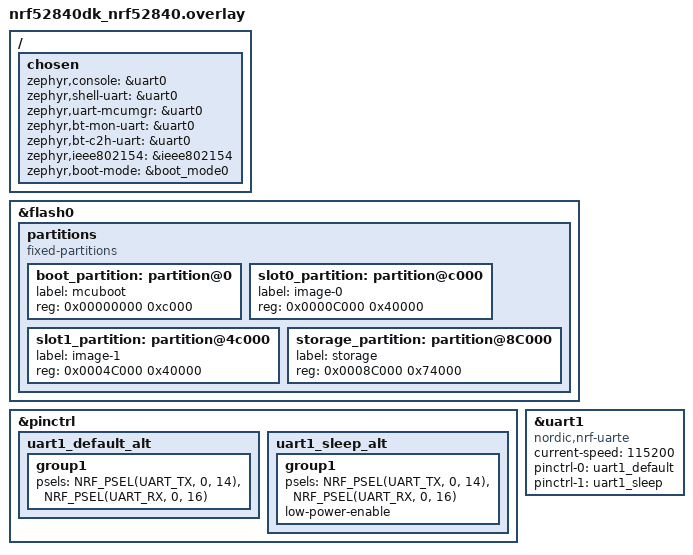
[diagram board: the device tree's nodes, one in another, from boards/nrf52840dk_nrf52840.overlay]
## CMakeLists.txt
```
cmake_minimum_required(VERSION 3.20.0)

set(CMAKE_EXPORT_COMPILE_COMMANDS ON)
find_package(Zephyr REQUIRED HINTS $ENV{ZEPHYR_BASE})
project(sample_with_mcuboot)

test_sysbuild()

target_sources(app PRIVATE src/main.c)
```

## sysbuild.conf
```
# Sysbuild configuration file.

# Enable MCUboot using overwrite only mode for this sample.
SB_CONFIG_BOOTLOADER_MCUBOOT=y
SB_CONFIG_MCUBOOT_MODE_OVERWRITE_ONLY=y
SB_CONFIG_MCUBOOT_MODE_SINGLE_APP=n

SB_CONFIG_BOOT_SIGNATURE_TYPE_ECDSA_P256=n
SB_CONFIG_BOOT_SIGNATURE_TYPE_NONE=y
SB_CONFIG_BOOT_SIGNATURE_TYPE_RSA=n

#
# Sysbuild image configuration
#

#
# Modules
#

SB_CONFIG_WARN_EXPERIMENTAL=y
SB_CONFIG_WARN_DEPRECATED=y

SB_CONFIG_BOOTLOADER_NONE=n 
SB_CONFIG_MCUBOOT_MODE_SINGLE_APP=n
# SB_CONFIG_MCUBOOT_MODE_SWAP_USING_OFFSET is not set
# SB_CONFIG_MCUBOOT_MODE_SWAP_USING_MOVE is not set
# SB_CONFIG_MCUBOOT_MODE_SWAP_WITHOUT_SCRATCH is not set
# SB_CONFIG_MCUBOOT_MODE_SWAP_SCRATCH is not set
SB_CONFIG_MCUBOOT_MODE_OVERWRITE_ONLY=y
# SB_CONFIG_MCUBOOT_MODE_DIRECT_XIP is not set
# SB_CONFIG_MCUBOOT_MODE_DIRECT_XIP_WITH_REVERT is not set
# SB_CONFIG_MCUBOOT_MODE_RAM_LOAD is not set
# SB_CONFIG_MCUBOOT_MODE_FIRMWARE_UPDATER=y
# SB_CONFIG_MCUBOOT_MODE_SINGLE_APP_RAM_LOAD is not set
SB_CONFIG_BOOT_SIGNATURE_TYPE_NONE=y
# SB_CONFIG_BOOT_SIGNATURE_TYPE_RSA is not set
# SB_CONFIG_BOOT_SIGNATURE_TYPE_ECDSA_P256 is not set
# SB_CONFIG_BOOT_SIGNATURE_TYPE_ED25519 is not set
```

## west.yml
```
manifest:
  version: 0.8

  projects:
    - name: zephyr
      url: https://github.com/zephyrproject-rtos/zephyr 
      revision: main
      import:
        file: west.yml 
        path-prefix: deps 
        name-allowlist:
          - zephyr
          - cmsis
          - cmsis_6 
          - hal_nordic
          - mcuboot
          - zcbor
          - mbedtls 

  self:
    path: app
```

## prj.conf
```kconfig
CONFIG_CBPRINTF_NANO=n

## subsys/logging/Kconfig
CONFIG_LOG=y
CONFIG_LOG_MODE_MINIMAL=n

## Kconfig.zephyr
CONFIG_STD_C23=y
CONFIG_CODING_GUIDELINE_CHECK=y
# CONFIG_DEBUG_OPTIMIZATIONS=y
CONFIG_SIZE_OPTIMIZATIONS_AGGRESSIVE=y
CONFIG_COMPILER_WARNINGS_AS_ERRORS=n  #  Kernal build fails
CONFIG_DEPRECATION_TEST=y
CONFIG_COMPILER_SAVE_TEMPS=y
CONFIG_MISRA_SANE=y
CONFIG_ASSERT_ON_ERRORS=y
# CONFIG_RUNTIME_ERROR_CHECK=y
CONFIG_OUTPUT_PRINT_MEMORY_USAGE=y
CONFIG_BUILD_OUTPUT_META=y
CONFIG_IS_BOOTLOADER=n
CONFIG_LEGACY_GENERATED_INCLUDE_PATH=n

# MCUBoot Kconfig.mcuboot 
CONFIG_BOOTLOADER_MCUBOOT=y
#CONFIG_MCUBOOT_IMGTOOL_OVERWRITE_ONLY=y
CONFIG_MCUBOOT_GENERATE_UNSIGNED_IMAGE=y
# CONFIG_MCUBOOT_GENERATE_CONFIRMED_IMAGE=y
#CONFIG_MCUBOOT_BOOTLOADER_MODE_SINGLE_APP=n
#CONFIG_MCUBOOT_BOOTLOADER_MODE_FIRMWARE_UPDATER=y
CONFIG_BOOT_IMAGE_ACCESS_HOOKS=n

#
#CONFIG_ACPI_SHELL=y 

# Shell Kconfig
CONFIG_SHELL=y
CONFIG_SHELL_MINIMAL=n  #  enable comfort features

# Flash
CONFIG_FLASH=y
CONFIG_STREAM_FLASH=y
CONFIG_STREAM_FLASH_PROGRESS=y
CONFIG_FLASH_MAP=y
CONFIG_STREAM_FLASH_INSPECT=y

# DFU Kconfig
CONFIG_IMG_MANAGER=y
CONFIG_MCUBOOT_IMG_MANAGER=y
CONFIG_MCUBOOT_SHELL=y
CONFIG_IMG_BLOCK_BUF_SIZE=1024
CONFIG_IMG_ERASE_PROGRESSIVELY=y
CONFIG_IMG_ENABLE_IMAGE_CHECK=y
CONFIG_UPDATEABLE_IMAGE_NUMBER=1


CONFIG_COUNTER=y
#CONFIG_EDAC=y 
CONFIG_HWINFO=y
CONFIG_I2C=y
#CONFIG_PLIC=y
CONFIG_LED=y
CONFIG_PWM=y
CONFIG_REGULATOR=y
CONFIG_RTC=y
CONFIG_SENSOR=y
CONFIG_STEPPER=y
CONFIG_CRC=y
#CONFIG_TASK_WDT=y
CONFIG_STREAM_FLASH=y
CONFIG_STDOUT_CONSOLE=y
CONFIG_FLASH=y
CONFIG_FLASH_MAP=y
CONFIG_SETTINGS=y
CONFIG_GPIO=y
CONFIG_RESET=y
# CONFIG_ASSERT is not set
# CONFIG_DEVICE_DEPS is not set
CONFIG_CONSOLE=y
CONFIG_REBOOT=y

CONFIG_SETTINGS_RUNTIME=y
CONFIG_NVS=y
CONFIG_SETTINGS_NVS=y
CONFIG_HEAP_MEM_POOL_SIZE=256
CONFIG_MPU_ALLOW_FLASH_WRITE=y


CONFIG_SETTINGS_SHELL=y
CONFIG_KERNEL_SHELL=y
CONFIG_CRC_SHELL=y
#CONFIG_TASK_WDT_SHELL=y
CONFIG_ISR_TABLE_SHELL=y
CONFIG_POSIX_ENV_SHELL=y
CONFIG_POSIX_UNAME_SHELL=y
CONFIG_SENSOR_SHELL=y
CONFIG_RTC_SHELL=y
#CONFIG_PLIC_SHELL=y
CONFIG_STEPPER_SHELL=y
CONFIG_ADC_SHELL=y
CONFIG_DAC_SHELL=y 
CONFIG_UART_SHELL=y 
CONFIG_PWM_SHELL=y 
#CONFIG_EDAC_SHELL=y
CONFIG_LED_SHELL=y
CONFIG_REGULATOR_SHELL=y
CONFIG_I2C_SHELL=y
CONFIG_HWINFO_SHELL=y
CONFIG_FLASH_SHELL=y
CONFIG_FLASH_SHELL_TEST_COMMANDS=y
CONFIG_COUNTER_SHELL=y
CONFIG_DEVICE_SHELL=y
CONFIG_DATE_SHELL=y
CONFIG_DEVMEM_SHELL=y
CONFIG_APP_VERSION_SHELL=y
CONFIG_KERNEL_SHELL=y


CONFIG_GEN_ISR_TABLES=y
CONFIG_INIT_STACKS=y
CONFIG_TIMESLICE_SIZE=20
CONFIG_FLASH_LOAD_OFFSET=0xc000
CONFIG_SYS_CLOCK_EXISTS=y
CONFIG_INIT_ARCH_HW_AT_BOOT=y
# CONFIG_BUILD_OUTPUT_S19 is not set
CONFIG_BUILD_OUTPUT_HEX=y
# CONFIG_POWER_DOMAIN is not set
# CONFIG_MFD is not set
# CONFIG_SCHED_CPU_MASK is not set
#
# Modules
#
# CONFIG_BUILD_ONLY_NO_BLOBS is not set

#CONFIG_MCUBOOT_IMGTOOL_OVERWRITE_ONLY=y

#
# On board MCUboot operation mode
#
# CONFIG_MCUBOOT_BOOTLOADER_MODE_SINGLE_APP is not set
# CONFIG_MCUBOOT_BOOTLOADER_MODE_SWAP_USING_OFFSET is not set
# CONFIG_MCUBOOT_BOOTLOADER_MODE_SWAP_USING_MOVE is not set
# CONFIG_MCUBOOT_BOOTLOADER_MODE_SWAP_WITHOUT_SCRATCH is not set
# CONFIG_MCUBOOT_BOOTLOADER_MODE_SWAP_SCRATCH is not set
CONFIG_MCUBOOT_BOOTLOADER_MODE_OVERWRITE_ONLY=y
# CONFIG_MCUBOOT_BOOTLOADER_MODE_RAM_LOAD is not set
# CONFIG_MCUBOOT_BOOTLOADER_MODE_RAM_LOAD_WITH_REVERT is not set
# CONFIG_MCUBOOT_BOOTLOADER_MODE_DIRECT_XIP is not set
# CONFIG_MCUBOOT_BOOTLOADER_MODE_DIRECT_XIP_WITH_REVERT is not set
# CONFIG_MCUBOOT_BOOTLOADER_MODE_FIRMWARE_UPDATER is not set
# CONFIG_MCUBOOT_BOOTLOADER_MODE_SINGLE_APP_RAM_LOAD is not set
# CONFIG_MCUBOOT_BOOTLOADER_NO_DOWNGRADE is not set
# CONFIG_MCUBOOT_BOOTLOADER_USES_SHA512 is not set
# CONFIG_MCUBOOT_BOOTLOADER_SIGNATURE_TYPE_PURE is not set
# end of On board MCUboot operation mode

CONFIG_MCUBOOT_BOOTUTIL_LIB=y
#
# DSP Options
#
# end of DSP Options

#
# Floating Point Options
#
# end of Floating Point Options

#
# Cache Options
#
# end of Cache Options

#
# Kernel Debugging and Metrics
#
CONFIG_BOOT_BANNER=y
CONFIG_BOOT_BANNER_STRING="Booting Zephyr OS build"
CONFIG_BOOT_DELAY=0

#
# Device Options
#
# CONFIG_DEVICE_MUTABLE is not set
CONFIG_DEVICE_DT_METADATA=y
CONFIG_DEVICE_DEINIT_SUPPORT=y
# end of Device Options

#
# Device Drivers
#
CONFIG_ADC=y
# CONFIG_AUDIO is not set
# CONFIG_AUXDISPLAY is not set
# CONFIG_BBRAM is not set
# CONFIG_CAN is not set
# CONFIG_CHARGER is not set
CONFIG_UART_CONSOLE=y
# CONFIG_UART_CONSOLE_DEBUG_SERVER_HOOKS is not set
# CONFIG_UART_CONSOLE_MCUMGR is not set
# CONFIG_RAM_CONSOLE is not set
# CONFIG_IPM_CONSOLE_SENDER is not set
# CONFIG_IPM_CONSOLE_RECEIVER is not set
# CONFIG_UART_MCUMGR is not set
# CONFIG_EFI_CONSOLE is not set
# CONFIG_COREDUMP_DEVICE is not set
#CONFIG_CRC_DRIVER=n
# CONFIG_CRYPTO is not set
CONFIG_DAC=y
# CONFIG_DAI is not set
# CONFIG_DEBUG_DRIVER is not set
# CONFIG_DISK_DRIVERS is not set
# CONFIG_DISPLAY is not set
# CONFIG_DMA is not set
# CONFIG_DP_DRIVER is not set
# CONFIG_EDAC is not set
# CONFIG_EEPROM is not set
# CONFIG_ENTROPY_GENERATOR is not set
# CONFIG_ESPI is not set

#
# Firmware drivers
#
# CONFIG_ARM_SCMI is not set
# end of Firmware drivers

# CONFIG_FPGA is not set
# CONFIG_FUEL_GAUGE is not set
# CONFIG_GNSS is not set
CONFIG_GPIO_SHELL=y
CONFIG_GPIO_SHELL_INFO_CMD=y
CONFIG_GPIO_SHELL_TOGGLE_CMD=y
CONFIG_GPIO_SHELL_BLINK_CMD=y
# CONFIG_GPIO_GET_DIRECTION is not set
# CONFIG_GPIO_GET_CONFIG is not set
# CONFIG_GPIO_HOGS is not set
# CONFIG_GPIO_ENABLE_DISABLE_INTERRUPT is not set

#
# Timer drivers
#
# CONFIG_TIMER_READS_ITS_FREQUENCY_AT_RUNTIME is not set
# CONFIG_SYSTEM_CLOCK_SLOPPY_IDLE is not set

# CONFIG_USB_BC12 is not set
# CONFIG_UDC_DRIVER is not set
# CONFIG_UHC_DRIVER is not set
# CONFIG_UVB is not set
# CONFIG_USB_DEVICE_DRIVER is not set

#
# USB common
#
# end of USB common

# CONFIG_USBC_TCPC_DRIVER is not set
# CONFIG_USBC_VBUS_DRIVER is not set
# CONFIG_USBC_PPC_DRIVER is not set
# CONFIG_VIDEO is not set
# CONFIG_VIRTIO is not set
# CONFIG_VIRTUALIZATION is not set
# CONFIG_W1 is not set
# CONFIG_TEE is not set
# end of Device Drivers


#
# C++ Language Support
#
# CONFIG_CPP is not set
# end of C++ Language Support

#
# Additional libraries
#

#
# Hash Function Support
#
# CONFIG_SYS_HASH_FUNC32 is not set
# end of Hash Function Support

#
# Hashmap (Hash Table) Support
#
# CONFIG_SYS_HASH_MAP is not set
# end of Hashmap (Hash Table) Support

#
# Heap and Memory Allocation
#
# CONFIG_SYS_HEAP_STRESS is not set
# CONFIG_SYS_HEAP_INFO is not set
CONFIG_SYS_HEAP_ALLOC_LOOPS=3
# CONFIG_SYS_HEAP_RUNTIME_STATS is not set
CONFIG_SYS_HEAP_ARRAY_SIZE=0
# CONFIG_SYS_HEAP_LISTENER is not set
CONFIG_SYS_HEAP_SMALL_ONLY=y
# CONFIG_SYS_HEAP_BIG_ONLY is not set
# CONFIG_SYS_HEAP_AUTO is not set
# CONFIG_MULTI_HEAP is not set
# CONFIG_SHARED_MULTI_HEAP is not set
# end of Heap and Memory Allocation

#
# Memory Blocks
#
CONFIG_SYS_MEM_BLOCKS=y
# end of Memory Blocks

# CONFIG_NET_BUF is not set

#
# OS Support Library
#
# CONFIG_FDTABLE is not set
CONFIG_CBPRINTF_COMPLETE=y
# CONFIG_CBPRINTF_NANO is not set
CONFIG_CBPRINTF_FULL_INTEGRAL=y
# CONFIG_CBPRINTF_REDUCED_INTEGRAL is not set
CONFIG_CBPRINTF_FP_SUPPORT=y
# CONFIG_CBPRINTF_FP_A_SUPPORT is not set
# CONFIG_CBPRINTF_LIBC_SUBSTS is not set
# CONFIG_CBPRINTF_PACKAGE_LONGDOUBLE is not set
# CONFIG_ZVFS is not set
# end of OS Support Library

#
# POSIX API Support
#


#
# POSIX Shell Utilities
#
CONFIG_POSIX_ENV_SHELL=y
# end of POSIX Shell Utilities
# end of POSIX API Support

# CONFIG_OPENAMP_RSC_TABLE is not set
# CONFIG_SMF is not set
CONFIG_LIBGCC_RTLIB=y

#
# Utility Library
#
# CONFIG_JSON_LIBRARY is not set
CONFIG_RING_BUFFER=y
# CONFIG_RING_BUFFER_LARGE is not set
CONFIG_NOTIFY=y
# CONFIG_BASE64 is not set
CONFIG_ONOFF=y
# CONFIG_UTF8 is not set
# CONFIG_COBS is not set
# end of Utility Library

#
# Universally Unique Identifier (UUID)
#
# CONFIG_UUID is not set
# end of Universally Unique Identifier (UUID)

# CONFIG_MIN_HEAP is not set
# end of Additional libraries

#
# Subsystems and OS Services
#
# CONFIG_BINDESC is not set
# CONFIG_BT is not set

#
# Controller Area Network (CAN) bus subsystem
#
# end of Controller Area Network (CAN) bus subsystem

# CONFIG_CONSOLE_SUBSYS is not set
# CONFIG_CPU_LOAD_METRIC is not set
# CONFIG_CRC is not set
# CONFIG_DAP is not set

#
# System Monitoring Options
#
# CONFIG_THREAD_ANALYZER is not set
# end of System Monitoring Options

#
# Debugging Options
#
# CONFIG_DEBUG is not set
# CONFIG_UBSAN is not set
# CONFIG_STACK_USAGE is not set
CONFIG_PRINTK=y
CONFIG_EARLY_CONSOLE=y
# CONFIG_FORCE_NO_ASSERT is not set
CONFIG_ASSERT_VERBOSE=y
# CONFIG_ASSERT_NO_FILE_INFO is not set
# CONFIG_ASSERT_NO_COND_INFO is not set
# CONFIG_ASSERT_NO_MSG_INFO is not set
# CONFIG_ASSERT_TEST is not set
# CONFIG_OVERRIDE_FRAME_POINTER_DEFAULT is not set
# CONFIG_DEBUG_THREAD_INFO is not set
# CONFIG_DEBUG_COREDUMP is not set
# CONFIG_SYMTAB is not set
# end of Debugging Options

# CONFIG_MIPI_STP_DECODER is not set
# CONFIG_CS_TRACE_DEFMT is not set
# CONFIG_CPU_LOAD is not set
CONFIG_CPU_LOAD_LOG_PERIODICALLY=0
# CONFIG_DISK_ACCESS is not set
# CONFIG_DSP is not set
# CONFIG_EMUL is not set
# CONFIG_CHARACTER_FRAMEBUFFER is not set

#
# File Systems
#
# CONFIG_FILE_SYSTEM_LIB_LINK is not set
# CONFIG_FILE_SYSTEM is not set
# end of File Systems

# CONFIG_GNSS_RTK is not set

#
# Inter Processor Communication
#
# CONFIG_RPMSG_SERVICE is not set
# CONFIG_IPC_SERVICE is not set
# end of Inter Processor Communication

# CONFIG_JWT is not set
# CONFIG_LLEXT is not set
# CONFIG_LLEXT_EDK is not set

#
# Logging
#
CONFIG_LOG_CORE_INIT_PRIORITY=0
CONFIG_LOG_MODE_DEFERRED=y
# CONFIG_LOG_MODE_IMMEDIATE is not set
# CONFIG_LOG_MODE_MINIMAL is not set
# CONFIG_LOG_FRONTEND is not set
# CONFIG_LOG_FRONTEND_OPT_API is not set
# CONFIG_LOG_CUSTOM_HEADER is not set
# CONFIG_LOG_MULTIDOMAIN is not set
CONFIG_LOG_FLUSH_SLEEP_US=10000

#
# Logging levels filtering
#
CONFIG_LOG_RUNTIME_FILTERING=y
CONFIG_LOG_DEFAULT_LEVEL=3
CONFIG_LOG_OVERRIDE_LEVEL=0
CONFIG_LOG_MAX_LEVEL=4
# end of Logging levels filtering

#
# Processing
#
CONFIG_LOG_PRINTK=y
CONFIG_LOG_MODE_OVERFLOW=y
# CONFIG_LOG_BLOCK_IN_THREAD is not set
CONFIG_LOG_PROCESS_TRIGGER_THRESHOLD=10
CONFIG_LOG_PROCESS_THREAD=y
CONFIG_LOG_PROCESS_THREAD_STARTUP_DELAY_MS=0
CONFIG_LOG_PROCESS_THREAD_SLEEP_MS=1000
CONFIG_LOG_PROCESS_THREAD_STACK_SIZE=768
# CONFIG_LOG_PROCESS_THREAD_CUSTOM_PRIORITY is not set
CONFIG_LOG_BUFFER_SIZE=1024
CONFIG_LOG_TRACE_SHORT_TIMESTAMP=y
# CONFIG_LOG_TIMESTAMP_64BIT is not set
# CONFIG_LOG_TIMESTAMP_USE_REALTIME is not set
# CONFIG_LOG_SPEED is not set
# end of Processing

#
# Output Formatting
#

#
# Prepend non-hexdump log message with function name
#
# CONFIG_LOG_FUNC_NAME_PREFIX_ERR is not set
# CONFIG_LOG_FUNC_NAME_PREFIX_WRN is not set
# CONFIG_LOG_FUNC_NAME_PREFIX_INF is not set
CONFIG_LOG_FUNC_NAME_PREFIX_DBG=y
# end of Prepend non-hexdump log message with function name

# CONFIG_LOG_MIPI_SYST_ENABLE is not set
# CONFIG_LOG_THREAD_ID_PREFIX is not set
# CONFIG_LOG_CUSTOM_FORMAT_SUPPORT is not set
CONFIG_LOG_BACKEND_SHOW_COLOR=y
# CONFIG_LOG_INFO_COLOR_GREEN is not set
# CONFIG_LOG_DBG_COLOR_BLUE is not set
CONFIG_LOG_TAG_MAX_LEN=0
CONFIG_LOG_OUTPUT_FORMAT_TIME_TIMESTAMP=y
# CONFIG_LOG_OUTPUT_FORMAT_LINUX_TIMESTAMP is not set
# CONFIG_LOG_OUTPUT_FORMAT_CUSTOM_TIMESTAMP is not set
# end of Output Formatting

#
# Backends
#
# CONFIG_LOG_BACKEND_SWO is not set
# CONFIG_LOG_BACKEND_UART is not set
# CONFIG_LOG_BACKEND_IPC_SERVICE is not set
# end of Backends

#
# Misc
#
# CONFIG_LOG_CMDS is not set
# CONFIG_LOG_USE_VLA is not set
CONFIG_LOG_SIMPLE_MSG_OPTIMIZE=y
# CONFIG_LOG_ALWAYS_RUNTIME is not set
# CONFIG_LOG_FMT_SECTION is not set
# CONFIG_LOG_FMT_STRING_VALIDATE is not set
# CONFIG_LOG_MEM_UTILIZATION is not set
CONFIG_LOG_FAILURE_REPORT_PERIOD=1000
# end of Misc

CONFIG_LOG_RATELIMIT=y
CONFIG_LOG_RATELIMIT_INTERVAL_MS=5000
CONFIG_LOG_OUTPUT=y
# end of Logging

CONFIG_MEM_ATTR=y
# CONFIG_MEM_ATTR_HEAP is not set

#
# Device Management
#

#
# Host command handler subsystem
#
# CONFIG_EC_HOST_CMD is not set
# end of Host command handler subsystem

# CONFIG_OSDP is not set
# end of Device Management

# CONFIG_MODBUS is not set
# CONFIG_MODEM_MODULES is not set

#
# Networking
#
# CONFIG_NETWORKING is not set
# end of Networking

#
# Power Management
#
# CONFIG_PM_POLICY_LATENCY_STANDALONE is not set
# end of Power Management

#
# Platform Management Communications Infrastructure (PMCI)
#
# CONFIG_MCTP is not set
# end of Platform Management Communications Infrastructure (PMCI)

#
# Portability
#
# end of Portability

# CONFIG_PROFILING is not set


CONFIG_RTIO=y

#
# SD
#
# CONFIG_MMC_STACK is not set
# CONFIG_SDMMC_STACK is not set
# CONFIG_SDIO_STACK is not set
# end of SD

# CONFIG_SECURE_STORAGE is not set
# CONFIG_SETTINGS
CONFIG_SHELL_MINIMAL=n
CONFIG_SHELL_DEVICE_HELPERS=y
# CONFIG_SHELL_THREAD_PRIORITY_OVERRIDE is not set
CONFIG_KERNEL_SHELL_PANIC_CMD=y
# CONFIG_STATS is not set

#
# Storage
#
CONFIG_FLASH_MAP=y
CONFIG_STREAM_FLASH=y
# end of Storage

# CONFIG_TASK_WDT is not set

#
# Testing
#
# CONFIG_ZTEST is not set
# CONFIG_ZTEST_MOCKING is not set
# CONFIG_ZTRESS is not set
# CONFIG_TEST is not set
# CONFIG_FORCE_COVERAGE is not set
# CONFIG_TEST_USERSPACE is not set
# end of Testing

# CONFIG_TIMING_FUNCTIONS is not set
# CONFIG_TRACING is not set
# CONFIG_USB_DEVICE_STACK is not set
# CONFIG_USB_DEVICE_STACK_NEXT is not set
# CONFIG_USB_HOST_STACK is not set
# CONFIG_USBC_STACK is not set
# CONFIG_ZBUS is not set
# CONFIG_MODULES is not set
# end of Subsystems and OS Services


#
# Build and Link Features
#


#
# Compiler Options
#
# CONFIG_STD_C90 is not set
# CONFIG_STD_C99 is not set
# CONFIG_STD_C11 is not set
# CONFIG_STD_C17 is not set
# CONFIG_GNU_C_EXTENSIONS is not set
# CONFIG_COMPILER_FREESTANDING is not set
# CONFIG_SIZE_OPTIMIZATIONS is not set
# CONFIG_SPEED_OPTIMIZATIONS is not set
# CONFIG_DEBUG_OPTIMIZATIONS is not set
# CONFIG_NO_OPTIMIZATIONS is not set
# CONFIG_COMPILER_WARNINGS_AS_ERRORS is not set
CONFIG_COMPILER_TRACK_MACRO_EXPANSION=y
CONFIG_COMPILER_COLOR_DIAGNOSTICS=y
# CONFIG_FORTIFY_SOURCE_NONE is not set
CONFIG_FORTIFY_SOURCE_COMPILE_TIME=y
# CONFIG_FORTIFY_SOURCE_RUN_TIME is not set
# end of Compiler Options

# CONFIG_NO_RUNTIME_CHECKS is not set
# CONFIG_RUNTIME_ERROR_CHECKS is not set

#
# Build Options
#
CONFIG_OUTPUT_STAT=y
# CONFIG_OUTPUT_SYMBOLS is not set
# CONFIG_CLEANUP_INTERMEDIATE_FILES is not set
CONFIG_BUILD_GAP_FILL_PATTERN=0xDE
# CONFIG_BUILD_NO_GAP_FILL is not set
# CONFIG_BUILD_OUTPUT_HEX_GAP_FILL is not set
# CONFIG_BUILD_OUTPUT_EXE is not set
# CONFIG_BUILD_OUTPUT_S19_GAP_FILL is not set
# CONFIG_BUILD_OUTPUT_UF2 is not set
# CONFIG_BUILD_OUTPUT_MOT is not set
# CONFIG_BUILD_OUTPUT_STRIPPED is not set
# CONFIG_BUILD_OUTPUT_COMPRESS_DEBUG_SECTIONS is not set
# CONFIG_BUILD_ALIGN_LMA is not set
# CONFIG_APPLICATION_DEFINED_SYSCALL is not set
# CONFIG_MAKEFILE_EXPORTS is not set
# CONFIG_BUILD_OUTPUT_META_STATE_PROPAGATE is not set
CONFIG_BUILD_OUTPUT_STRIP_PATHS=y
CONFIG_CHECK_INIT_PRIORITIES=y
# CONFIG_EMIT_ALL_SYSCALLS is not set
# end of Build Options

CONFIG_WARN_DEPRECATED=y
# CONFIG_WARN_EXPERIMENTAL is not set
CONFIG_ENFORCE_ZEPHYR_STDINT=y
# end of Build and Link Features

#
# Boot Options
#
# CONFIG_IS_BOOTLOADER is not set
# CONFIG_BOOTLOADER_BOSSA is not set
# end of Boot Options

#
# Compatibility
#
CONFIG_LEGACY_GENERATED_INCLUDE_PATH=y
# end of Compatibility
```

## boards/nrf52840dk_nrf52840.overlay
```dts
/ {
	chosen {
		zephyr,console = &uart0;
		zephyr,shell-uart = &uart0;
		zephyr,uart-mcumgr = &uart0;
		zephyr,bt-mon-uart = &uart0;
		zephyr,bt-c2h-uart = &uart0;
		zephyr,ieee802154 = &ieee802154;
		zephyr,boot-mode = &boot_mode0;
	};
};

/delete-node/ &qspi;

&flash0 {
    /delete-node/ partitions;
};
&flash0 {
	partitions {
		compatible = "fixed-partitions";
		#address-cells = <1>;
		#size-cells = <1>;

		boot_partition: partition@0 {
			label = "mcuboot";
			reg = <0x00000000 0xc000>;
		};

		slot0_partition: partition@c000 {
			label = "image-0";
			reg = <0x0000C000 0x40000>;
		};

		slot1_partition: partition@4c000 {
			label = "image-1";
			reg = <0x0004C000 0x40000>;
		};

		storage_partition: partition@8C000 {
			label = "storage";
			reg = <0x0008C000 0x74000>;
		};
	};
};

&pinctrl {
   uart1_default_alt: uart1_default_alt {
      group1 {
         psels = <NRF_PSEL(UART_TX, 0, 14)>,
                 <NRF_PSEL(UART_RX, 0, 16)>;
      };
   };
   /* required if CONFIG_PM_DEVICE=y */
   uart1_sleep_alt: uart1_sleep_alt {
      group1 {
         psels = <NRF_PSEL(UART_TX, 0, 14)>,
                 <NRF_PSEL(UART_RX, 0, 16)>;
         low-power-enable;
      };
   };
};

&uart1 {
	compatible = "nordic,nrf-uarte";
	status = "okay";
	current-speed = <115200>;
	pinctrl-0 = <&uart1_default>;
	pinctrl-1 = <&uart1_sleep>;
	pinctrl-names = "default", "sleep";
};
```

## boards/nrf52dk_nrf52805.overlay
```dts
	chosen {
		zephyr,console = &uart0;
		zephyr,shell-uart = &uart0;
		zephyr,uart-mcumgr = &uart0;
		zephyr,bt-mon-uart = &uart0;
		zephyr,bt-c2h-uart = &uart0;
		zephyr,sram = &sram0;
		zephyr,flash = &flash0;
		zephyr,code-partition = &slot0_partition;
	};
```

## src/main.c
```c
/*
 * Copyright (c) 2022 Nordic Semiconductor
 *
 * SPDX-License-Identifier: Apache-2.0
 */

#include <zephyr/app_version.h>
#include <zephyr/dfu/mcuboot.h>
#include <zephyr/kernel.h>
#include <zephyr/linker/linker-defs.h>
#include <zephyr/shell/shell.h>

static int version_cmd_handler(const struct shell *sh, size_t argc, char **argv,
                               void *data) {
  shell_print(sh, "%s\n", APP_VERSION_STRING);
  return 0;
}

SHELL_CMD_REGISTER(version, NULL, "Print application version.",
                   version_cmd_handler);
int main(void) {
  printk("Address of sample %p\n", (void *)__rom_region_start);
  printk("Hello sysbuild with mcuboot! %s\n", CONFIG_BOARD);

  while (true) {
    k_sleep(K_MSEC(1000)); // sleep for 1 second
  }
  return 0;
}
```
